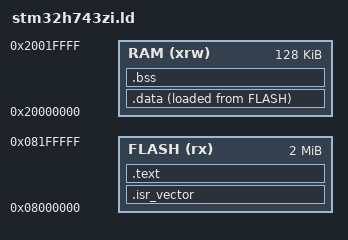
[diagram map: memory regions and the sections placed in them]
ENTRY(Reset_Handler)

MEMORY
{
  FLASH (rx)  : ORIGIN = 0x08000000, LENGTH = 2048K
  RAM   (xrw) : ORIGIN = 0x20000000, LENGTH = 128K
}

__StackTop = ORIGIN(RAM) + LENGTH(RAM);
__StackLimit = __StackTop - 0x2000;

SECTIONS
{
  .isr_vector :
  {
    . = ALIGN(4);
    KEEP(*(.isr_vector))
    . = ALIGN(4);
  } > FLASH

  .text :
  {
    . = ALIGN(4);
    *(.text*)
    *(.rodata*)
    *(.glue_7)
    *(.glue_7t)
    . = ALIGN(4);
    _etext = .;
  } > FLASH

  _sidata = LOADADDR(.data);

  .data :
  {
    . = ALIGN(4);
    _sdata = .;
    *(.data*)
    . = ALIGN(4);
    _edata = .;
  } > RAM AT > FLASH

  .bss (NOLOAD) :
  {
    . = ALIGN(4);
    _sbss = .;
    *(.bss*)
    *(COMMON)
    . = ALIGN(4);
    _ebss = .;
  } > RAM

  . = ALIGN(8);
  end = .;
}
